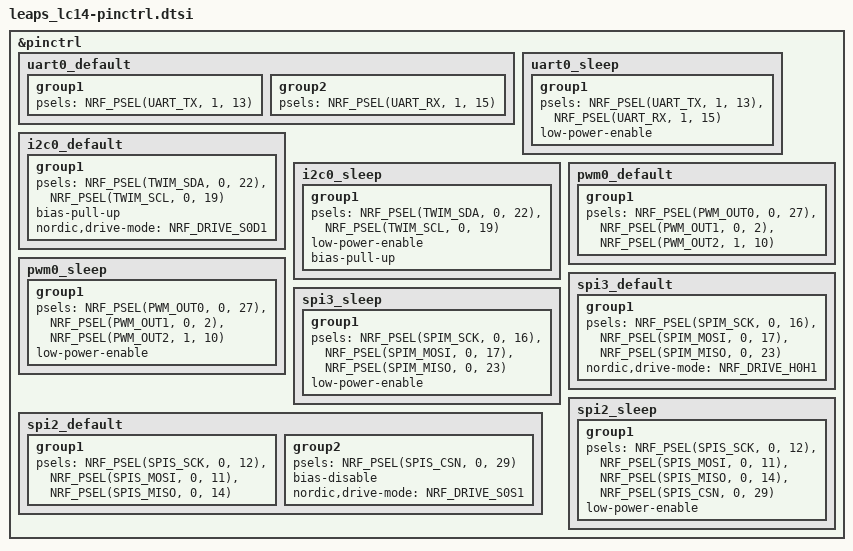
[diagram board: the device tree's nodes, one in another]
/*
 * LEAPS - Low Energy Accurate Positioning System.
 *
 * Copyright (c) 2022 Nordic Semiconductor
 *
 * SPDX-License-Identifier: Apache-2.0
 */

&pinctrl {
	uart0_default: uart0_default {
		group1 {
			psels = <NRF_PSEL(UART_TX, 1, 13)>;
		};
		group2 {
			psels = <NRF_PSEL(UART_RX, 1, 15)>;
		};
	};

	uart0_sleep: uart0_sleep {
		group1 {
			psels = <NRF_PSEL(UART_TX, 1, 13)>,
					<NRF_PSEL(UART_RX, 1, 15)>;
			low-power-enable;
		};
	};

	i2c0_default: i2c0_default {
		group1 {
			psels = <NRF_PSEL(TWIM_SDA, 0, 22)>,
				<NRF_PSEL(TWIM_SCL, 0, 19)>;
			bias-pull-up;
			nordic,drive-mode = <NRF_DRIVE_S0D1>;
		};
	};

	i2c0_sleep: i2c0_sleep {
		group1 {
			psels = <NRF_PSEL(TWIM_SDA, 0, 22)>,
				<NRF_PSEL(TWIM_SCL, 0, 19)>;
			low-power-enable;
			bias-pull-up;
		};
	};

	pwm0_default: pwm0_default {
		group1 {
			psels = <NRF_PSEL(PWM_OUT0, 0, 27)>,
					<NRF_PSEL(PWM_OUT1, 0, 2)>,
					<NRF_PSEL(PWM_OUT2, 1, 10)>;
		};
	};

	pwm0_sleep: pwm0_sleep {
		group1 {
			psels = <NRF_PSEL(PWM_OUT0, 0, 27)>,
					<NRF_PSEL(PWM_OUT1, 0, 2)>,
					<NRF_PSEL(PWM_OUT2, 1, 10)>;
			low-power-enable;
		};
	};

	spi3_default: spi3_default {
		group1 {
			psels = <NRF_PSEL(SPIM_SCK, 0, 16)>,
				<NRF_PSEL(SPIM_MOSI, 0, 17)>,
				<NRF_PSEL(SPIM_MISO, 0, 23)>;
			nordic,drive-mode = <NRF_DRIVE_H0H1>;
		};
	};

	spi3_sleep: spi3_sleep {
		group1 {
			psels = <NRF_PSEL(SPIM_SCK, 0, 16)>,
				<NRF_PSEL(SPIM_MOSI, 0, 17)>,
				<NRF_PSEL(SPIM_MISO, 0, 23)>;
			low-power-enable;
		};
	};

	spi2_default: spi2_default {
		group1 {
			psels = <NRF_PSEL(SPIS_SCK, 0, 12)>,
				<NRF_PSEL(SPIS_MOSI, 0, 11)>,
				<NRF_PSEL(SPIS_MISO, 0, 14)>;
		};
		group2 {
			psels = <NRF_PSEL(SPIS_CSN, 0, 29)>;
			bias-disable;
			nordic,drive-mode = <NRF_DRIVE_S0S1>;
		};
	};

	spi2_sleep: spi2_sleep {
		group1 {
			psels = <NRF_PSEL(SPIS_SCK, 0, 12)>,
				<NRF_PSEL(SPIS_MOSI, 0, 11)>,
				<NRF_PSEL(SPIS_MISO, 0, 14)>,
				<NRF_PSEL(SPIS_CSN, 0, 29)>;
			low-power-enable;
		};
	};

};
